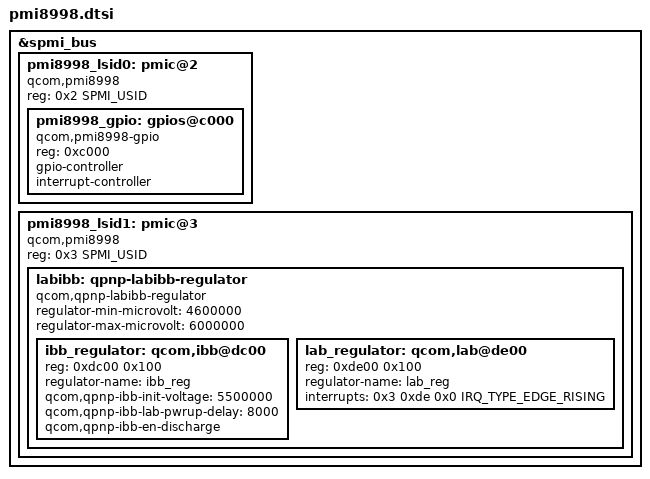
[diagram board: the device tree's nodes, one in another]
// SPDX-License-Identifier: GPL-2.0
#include <dt-bindings/interrupt-controller/irq.h>
#include <dt-bindings/spmi/spmi.h>

&spmi_bus {
	pmi8998_lsid0: pmic@2 {
		compatible = "qcom,pmi8998", "qcom,spmi-pmic";
		reg = <0x2 SPMI_USID>;
		#address-cells = <1>;
		#size-cells = <0>;

		pmi8998_gpio: gpios@c000 {
			compatible = "qcom,pmi8998-gpio", "qcom,spmi-gpio";
			reg = <0xc000>;
			gpio-controller;
			#gpio-cells = <2>;
			interrupt-controller;
			#interrupt-cells = <2>;
		};
	};

	pmi8998_lsid1: pmic@3 {
		compatible = "qcom,pmi8998", "qcom,spmi-pmic";
		reg = <0x3 SPMI_USID>;
		#address-cells = <1>;
		#size-cells = <0>;

		labibb: qpnp-labibb-regulator {
			compatible = "qcom,qpnp-labibb-regulator";
			#address-cells = <1>;
			#size-cells = <1>;
			status = "okay";
			regulator-min-microvolt = <4600000>;
                        regulator-max-microvolt = <6000000>;

			ibb_regulator: qcom,ibb@dc00 {
				reg = <0xdc00 0x100>;
				reg-names = "ibb_reg";
				regulator-name = "ibb_reg";

				interrupt-names = "ibb-sc-err";
				qcom,qpnp-ibb-init-voltage = <5500000>;
				qcom,qpnp-ibb-lab-pwrup-delay = <8000>;
				qcom,qpnp-ibb-en-discharge;
			};

			lab_regulator: qcom,lab@de00 {
				reg = <0xde00 0x100>;
				reg-names = "lab";
				regulator-name = "lab_reg";

				interrupts = <0x3 0xde 0x0
						IRQ_TYPE_EDGE_RISING>;
				interrupt-names = "lab-vreg-ok", "lab-sc-err";
			};
		};
	};
};
